# PIC32CX5112MTSH128S1 register map
Vendor: Microchip Technology; Series: PIC32CXMTSH; File version: 0
CPU: CM4 r0p1, little endian, MPU, FPU, 4 interrupt priority bits, 96 interrupts
Registers are 32-bit, read-write, reset 0x0 unless marked. A register's access mark holds for its fields unless they carry their own. Offsets are from the block's base; [hi:lo] are bit positions; {n}, {i} and the like mark numbered series.

## DWT — Data Watchpoint and Trace Register
Base 0xE0001000
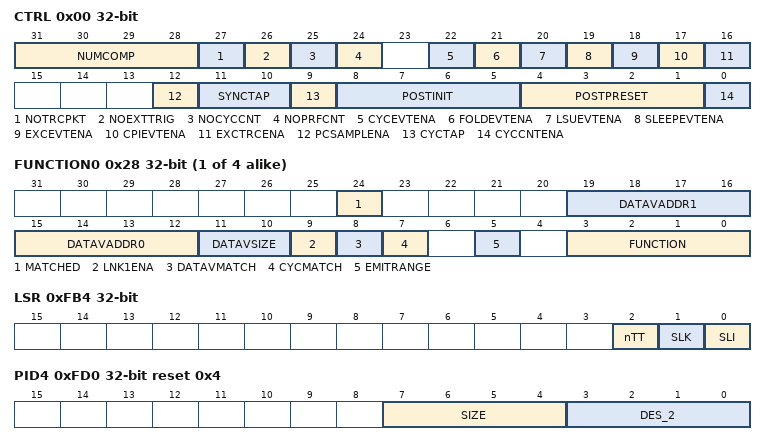
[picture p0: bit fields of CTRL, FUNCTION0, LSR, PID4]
0x00 CTRL — Control Register
  [31:28] NUMCOMP — Number of comparators implemented
  [27] NOTRCPKT — Shows whether the implementation supports trace sampling and exception tracing
  [26] NOEXTTRIG — Shows whether the implementation includes external match signals, CMPMATCH[N]
  [25] NOCYCCNT — Shows whether the implementation supports a cycle counter
  [24] NOPRFCNT — Shows whether the implementation supports the profiling counters
  [22] CYCEVTENA — Enables POSTCNT underflow Event counter packets generation
  [21] FOLDEVTENA — Enables generation of the Folded-instruction counter overflow event
  [20] LSUEVTENA — nables generation of the LSU counter overflow event
  [19] SLEEPEVTENA — Enables generation of the Sleep counter overflow event
  [18] EXCEVTENA — Enables generation of the Exception overhead counter overflow event
  [17] CPIEVTENA — Enables generation of the CPI counter overflow event
  [16] EXCTRCENA — Enables generation of exception trace
  [12] PCSAMPLENA — Enables use of POSTCNT counter as a timer for Periodic PC sample packet generation
  [11:10] SYNCTAP — Selects the position of the synchronization packet counter tap on the CYCCNT counter
  [9] CYCTAP — Selects the position of the POSTCNT tap on the CYCCNT counter
  [8:5] POSTINIT — Initial value for the POSTCNT counter
  [4:1] POSTPRESET — Reload value for the POSTCNT counter
  [0] CYCCNTENA — Enables CYCCNT
0x04 CYCCNT — Cycle Count Register
0x08 CPICNT — CPI Count Register
  [7:0] CPICNT — Base instruction overhead counter
0x0C EXCCNT — Exception Overhead Count Register
  [7:0] EXCCNT — The exception overhead counter
0x10 SLEEPCNT — Sleep Count Register
  [7:0] SLEEPCNT — Sleep counter
0x14 LSUCNT — LSU Count Register
  [7:0] LSUCNT — Load-store overhead counter
0x18 FOLDCNT — Folded-instruction Count Register
  [7:0] FOLDCNT — Folded instruction counter
0x1C PCSR ro — Program Counter Sample Register
{0x20+0x10*i} COMP{i} (i=0..3) — Comparator Register {i}
{0x24+0x10*i} MASK{i} (i=0..3) — Mask Register {i}
  [4:0] MASK — The size of the ignore mask
{0x28+0x10*i} FUNCTION{i} (i=0..3) — Function Register {i}
  [24] MATCHED, [19:16] DATAVADDR1, [15:12] DATAVADDR0, [11:10] DATAVSIZE, [9] LNK1ENA, [8] DATAVMATCH, [7] CYCMATCH, [5] EMITRANGE, [3:0] FUNCTION
0xFB0 LAR wo — DWT Software Lock Access Register
  [31:0] KEY — Lock access control
    0xC5ACCE55=UNLOCK (Unlock key value)
0xFB4 LSR ro — DWT Software Lock Status Register
  [2] nTT — Not thirty-two bit
  [1] SLK — Software Lock status
  [0] SLI — Software Lock implemented
0xFD0 PID4 ro reset 0x4 — DWT Peripheral Identification Register 4
  [7:4] SIZE — 4KB count
  [3:0] DES_2 — JEP106 continuation code
{0xFC0+4i} PID{i} ro (i=5..7) — DWT Peripheral Identification Register {i}
0xFE0 PID0 ro reset 0x2 — DWT Peripheral Identification Register 0
  [7:0] PART_0 — Part number bits[7:0]
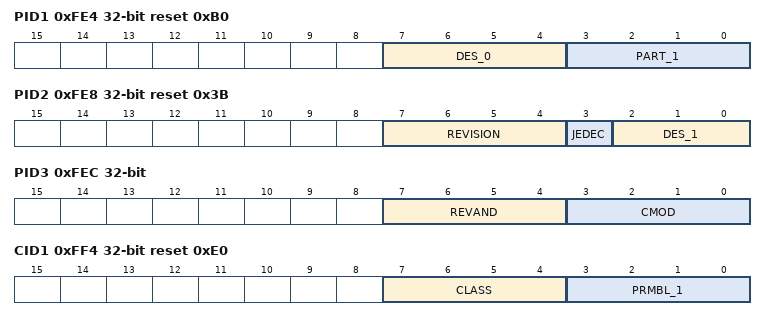
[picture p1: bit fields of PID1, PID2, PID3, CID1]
0xFE4 PID1 ro reset 0xB0 — DWT Peripheral Identification Register 1
  [7:4] DES_0 — JEP106 identification code bits [3:0]
  [3:0] PART_1 — Part number bits[11:8]
0xFE8 PID2 ro reset 0x3B — DWT Peripheral Identification Register 2
  [7:4] REVISION — Component revision
  [3] JEDEC — JEDEC assignee value is used
  [2:0] DES_1 — JEP106 identification code bits[6:4]
0xFEC PID3 ro — DWT Peripheral Identification Register 3
  [7:4] REVAND
  [3:0] CMOD — Customer Modified
0xFF0 CID0 ro reset 0xD — DWT Component Identification Register 0
  [7:0] PRMBL_0 — CoreSight component identification preamble
0xFF4 CID1 ro reset 0xE0 — DWT Component Identification Register 1
  [7:4] CLASS — CoreSight component class
  [3:0] PRMBL_1 — CoreSight component identification preamble
0xFF8 CID2 ro reset 0x5 — DWT Component Identification Register 2
  [7:0] PRMBL_2 — CoreSight component identification preamble
0xFFC CID3 ro reset 0xB1 — DWT Component Identification Register 3
  [7:0] PRMBL_3 — CoreSight component identification preamble
